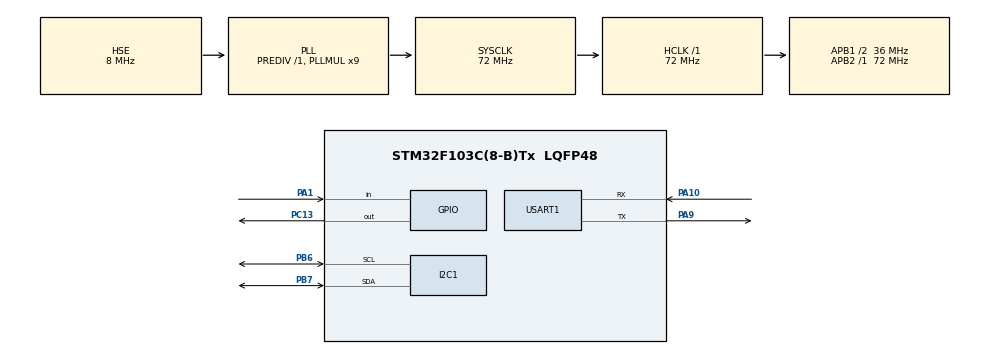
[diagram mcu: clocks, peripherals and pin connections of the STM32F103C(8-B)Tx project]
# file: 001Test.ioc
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Dma.Request0=USART1_RX
Dma.Request1=USART1_TX
Dma.USART1_RX.0.Direction=DMA_PERIPH_TO_MEMORY
Dma.USART1_RX.0.Instance=DMA1_Channel5
Dma.USART1_RX.0.MemDataAlignment=DMA_MDATAALIGN_BYTE
Dma.USART1_RX.0.MemInc=DMA_MINC_ENABLE
Dma.USART1_RX.0.Mode=DMA_NORMAL
Dma.USART1_RX.0.PeriphDataAlignment=DMA_PDATAALIGN_BYTE
Dma.USART1_RX.0.PeriphInc=DMA_PINC_DISABLE
Dma.USART1_RX.0.Priority=DMA_PRIORITY_LOW
Dma.USART1_TX.1.Direction=DMA_MEMORY_TO_PERIPH
Dma.USART1_TX.1.Instance=DMA1_Channel4
Dma.USART1_TX.1.MemDataAlignment=DMA_MDATAALIGN_BYTE
Dma.USART1_TX.1.MemInc=DMA_MINC_ENABLE
Dma.USART1_TX.1.Mode=DMA_NORMAL
Dma.USART1_TX.1.PeriphDataAlignment=DMA_PDATAALIGN_BYTE
Dma.USART1_TX.1.PeriphInc=DMA_PINC_DISABLE
Dma.USART1_TX.1.Priority=DMA_PRIORITY_LOW
FREERTOS.Tasks01=defaultTask,24,128,StartDefaultTask,Default,NULL,Dynamic,NULL,NULL
I2C1.I2C_Mode=I2C_Fast
Mcu.Family=STM32F1
Mcu.Name=STM32F103C(8-B)Tx
Mcu.Package=LQFP48
NVIC.DMA1_Channel4_IRQn=true\:5\:0\:false\:false\:true\:true\:false\:true
NVIC.DMA1_Channel5_IRQn=true\:5\:0\:false\:false\:true\:true\:false\:true
NVIC.PriorityGroup=NVIC_PRIORITYGROUP_4
NVIC.TIM4_IRQn=true\:0\:0\:false\:false\:true\:false\:false\:true
NVIC.TimeBase=TIM4_IRQn
NVIC.TimeBaseIP=TIM4
NVIC.USART1_IRQn=true\:5\:0\:false\:false\:true\:true\:true\:true
PA1.GPIO_PuPd=GPIO_PULLUP
PA1.Signal=GPIO_Input
PA10.Mode=Asynchronous
PA10.Signal=USART1_RX
PA13.Mode=Serial_Wire
PA13.Signal=SYS_JTMS-SWDIO
PA14.Mode=Serial_Wire
PA14.Signal=SYS_JTCK-SWCLK
PA9.Mode=Asynchronous
PA9.Signal=USART1_TX
PB6.Mode=I2C
PB6.Signal=I2C1_SCL
PB7.Mode=I2C
PB7.Signal=I2C1_SDA
PC13-TAMPER-RTC.Signal=GPIO_Output
PD0-OSC_IN.Mode=HSE-External-Oscillator
PD0-OSC_IN.Signal=RCC_OSC_IN
PD1-OSC_OUT.Mode=HSE-External-Oscillator
PD1-OSC_OUT.Signal=RCC_OSC_OUT
ProjectManager.HeapSize=0x200
ProjectManager.StackSize=0x400
ProjectManager.TargetToolchain=MDK-ARM V5.27
RCC.AHBFreq_Value=72000000
RCC.APB1CLKDivider=RCC_HCLK_DIV2
RCC.APB1Freq_Value=36000000
RCC.APB1TimFreq_Value=72000000
RCC.APB2Freq_Value=72000000
RCC.APB2TimFreq_Value=72000000
RCC.HCLKFreq_Value=72000000
RCC.PLLMUL=RCC_PLL_MUL9
RCC.PLLSourceVirtual=RCC_PLLSOURCE_HSE
RCC.SYSCLKFreq_VALUE=72000000
RCC.SYSCLKSource=RCC_SYSCLKSOURCE_PLLCLK
RCC.USBFreq_Value=72000000
USART1.VirtualMode=VM_ASYNC
VP_FREERTOS_VS_CMSIS_V2.Mode=CMSIS_V2
VP_SYS_VS_tim4.Mode=TIM4
board=custom

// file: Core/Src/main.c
/* USER CODE BEGIN Header */
/**
  ******************************************************************************
  * @file           : main.c
  * @brief          : Main program body
  ******************************************************************************
  * @attention
  *
  * <h2><center>&copy; Copyright (c) 2026 STMicroelectronics.
  * All rights reserved.</center></h2>
  *
  * This software component is licensed by ST under BSD 3-Clause license,
  * the "License"; You may not use this file except in compliance with the
  * License. You may obtain a copy of the License at:
  *                        opensource.org/licenses/BSD-3-Clause
  *
  ******************************************************************************
  */
/* USER CODE END Header */
#include "main.h"
#include "cmsis_os.h"
#include "dma.h"
#include "i2c.h"
#include "usart.h"
#include "gpio.h"

/* USER CODE BEGIN Includes */
#include "oled.h"		/* 调度器启动前先把屏幕点亮 */
/* USER CODE END Includes */

void SystemClock_Config(void);
void MX_FREERTOS_Init(void);

int main(void)
{
  /* MCU Configuration--------------------------------------------------------*/

  /* Reset of all peripherals, Initializes the Flash interface and the Systick. */
  HAL_Init();

  /* Configure the system clock */
  SystemClock_Config();

  /* Initialize all configured peripherals */
  MX_GPIO_Init();
  MX_DMA_Init();
  MX_USART1_UART_Init();
  MX_I2C1_Init();
  /* USER CODE BEGIN 2 */

  OLED_Init();
  /* USER CODE END 2 */

  /* Init scheduler */
  osKernelInitialize();  /* Call init function for freertos objects (in freertos.c) */
  MX_FREERTOS_Init();
  /* Start scheduler */
  osKernelStart();

  /* We should never get here as control is now taken by the scheduler */
  /* Infinite loop */
  while (1)
  {

  }
}

void SystemClock_Config(void)
{
  RCC_OscInitTypeDef RCC_OscInitStruct = {0};
  RCC_ClkInitTypeDef RCC_ClkInitStruct = {0};

  /** Initializes the RCC Oscillators according to the specified parameters
  * in the RCC_OscInitTypeDef structure.
  */
  RCC_OscInitStruct.OscillatorType = RCC_OSCILLATORTYPE_HSE;
  RCC_OscInitStruct.HSEState = RCC_HSE_ON;
  RCC_OscInitStruct.HSEPredivValue = RCC_HSE_PREDIV_DIV1;
  RCC_OscInitStruct.HSIState = RCC_HSI_ON;
  RCC_OscInitStruct.PLL.PLLState = RCC_PLL_ON;
  RCC_OscInitStruct.PLL.PLLSource = RCC_PLLSOURCE_HSE;
  RCC_OscInitStruct.PLL.PLLMUL = RCC_PLL_MUL9;
  if (HAL_RCC_OscConfig(&RCC_OscInitStruct) != HAL_OK)
  {
    Error_Handler();
  }
  /** Initializes the CPU, AHB and APB buses clocks
  */
  RCC_ClkInitStruct.ClockType = RCC_CLOCKTYPE_HCLK|RCC_CLOCKTYPE_SYSCLK
                              |RCC_CLOCKTYPE_PCLK1|RCC_CLOCKTYPE_PCLK2;
  RCC_ClkInitStruct.SYSCLKSource = RCC_SYSCLKSOURCE_PLLCLK;
  RCC_ClkInitStruct.AHBCLKDivider = RCC_SYSCLK_DIV1;
  RCC_ClkInitStruct.APB1CLKDivider = RCC_HCLK_DIV2;
  RCC_ClkInitStruct.APB2CLKDivider = RCC_HCLK_DIV1;

  if (HAL_RCC_ClockConfig(&RCC_ClkInitStruct, FLASH_LATENCY_2) != HAL_OK)
  {
    Error_Handler();
  }
}

/* USER CODE BEGIN 4 */

void HAL_TIM_PeriodElapsedCallback(TIM_HandleTypeDef *htim)
{
  /* USER CODE BEGIN Callback 0 */

  /* USER CODE END Callback 0 */
  if (htim->Instance == TIM4) {
    HAL_IncTick();
  }
  /* USER CODE BEGIN Callback 1 */

  /* USER CODE END Callback 1 */
}
/* USER CODE END 4 */

void Error_Handler(void)
{
  __disable_irq();
  while (1)
  {
  }
}

/************************ (C) COPYRIGHT STMicroelectronics *****END OF FILE****/

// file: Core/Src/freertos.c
/* USER CODE BEGIN Header */
/**
  ******************************************************************************
  * File Name          : freertos.c
  * Description        : Code for freertos applications
  ******************************************************************************
  * @attention
  *
  * <h2><center>&copy; Copyright (c) 2026 STMicroelectronics.
  * All rights reserved.</center></h2>
  *
  * This software component is licensed by ST under Ultimate Liberty license
  * SLA0044, the "License"; You may not use this file except in compliance with
  * the License. You may obtain a copy of the License at:
  *                             www.st.com/SLA0044
  *
  ******************************************************************************
  */
/* USER CODE END Header */

#include "FreeRTOS.h"
#include "task.h"
#include "main.h"
#include "cmsis_os.h"

/* USER CODE BEGIN Includes */
#include "app_rtos.h"		/* 三个应用任务、信号量、互斥锁都在这里创建 */
/* USER CODE END Includes */

void MX_FREERTOS_Init(void); /* (MISRA C 2004 rule 8.1) */

void MX_FREERTOS_Init(void) {

  /* USER CODE BEGIN RTOS_MUTEX */
  /* 互斥锁在 app_rtos.c 的 AppRTOS_Init() 里创建（要开优先级继承），
     不在 CubeMX 这里创建，免得同一类对象分两处管理。 */
  /* USER CODE END RTOS_MUTEX */

  /* Create the thread(s) */
  /* USER CODE BEGIN RTOS_THREADS */
  /* ====================================================================
   * 创建应用任务与任务间通信对象
   *
   * CubeMX 里的 defaultTask 已经删掉（它什么都不做，白占 512 字节栈），
   * 三个真正的任务由 AppRTOS_Init() 创建：
   *     IMU_Task   osPriorityRealtime      100Hz 采样 + 姿态解算
   *     UART_Task  osPriorityHigh          串口收发 + 1Hz 上报
   *     OLED_Task  osPriorityAboveNormal   10Hz 刷屏
   *
   * 位置很关键：必须在 osKernelInitialize() 之后（main 里已经调过）、
   * osKernelStart() 之前。放早了对象创建会失败，放晚了任务来不及启动。
   *
   * 创建失败（通常是 configTOTAL_HEAP_SIZE 不够）时，
   * AppRTOS_Init() 会在 OLED 上显示错误码并停住，不会返回。
   * ================================================================== */
  (void)AppRTOS_Init();
  /* USER CODE END RTOS_THREADS */

}

/************************ (C) COPYRIGHT STMicroelectronics *****END OF FILE****/
